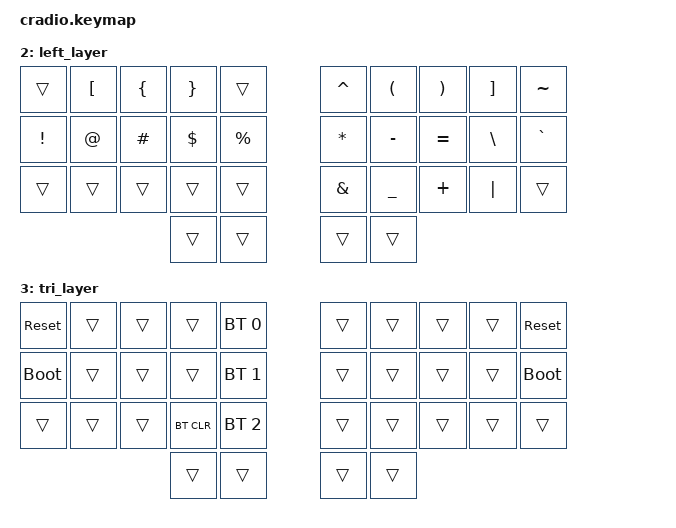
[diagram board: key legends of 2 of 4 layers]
// Copyright (c) 2022 The ZMK Contributors
// SPDX-License-Identifier: MIT

#include <behaviors.dtsi>
#include <dt-bindings/zmk/keys.h>
#include <dt-bindings/zmk/bt.h>


/ {
    behaviors {
        ht: hold_tap {
            label = "hold_tap";
            compatible = "zmk,behavior-hold-tap";
            #binding-cells = <2>;
            flavor = "tap-preferred";
            tapping-term-ms = <220>;
            quick-tap-ms = <150>;
            global-quick-tap;
            bindings = <&kp>, <&kp>;
        };
    };

    conditional_layers {
        compatible = "zmk,conditional-layers";
        tri_layer {
            if-layers = <1 2>;
            then-layer = <3>;
        };
    };

// Home row mods macro
#define HRML(k1,k2,k3,k4) &ht LSHFT k1  &ht LALT k2  &ht LCTRL k3  &ht LGUI k4
#define HRMR(k1,k2,k3,k4) &ht RGUI k1  &ht RCTRL k2  &ht RALT k3  &ht RSHFT k4
    keymap {
        compatible = "zmk,keymap";
        default_layer {
            bindings = <
        //╭──────────┬──────────┬──────────┬──────────┬──────────╮   ╭──────────┬──────────┬──────────┬──────────┬──────────╮
        //│  Q       │  W       │  F       │  P       │  G       │   │  J       │  L       │  U       │  Y       │  ; :     │
            &kp Q       &kp W      &kp E      &kp R      &kp T          &kp Y      &kp U      &kp I      &kp O      &kp P
        //├──────────┼──────────┼──────────┼──────────┼──────────┤   ├──────────┼──────────┼──────────┼──────────┼──────────┤
        //│  A       │  R       │  S       │  T       │  D       │   │  H       │  N       │  E       │  I       │  O       │
            HRML(A,        S,         D,         F)     &kp G          &kp H      HRMR(J,    K,         L,         SEMI)
        //├──────────┼──────────┼──────────┼──────────┼──────────┤   ├──────────┼──────────┼──────────┼──────────┼──────────┤
        //│  / ?     │  Z       │  X       │  C       │  V       │   │  B       │  K       │  M       │ , <      │ . >      │
            &kp FSLH &kp Z   &kp X      &kp C      &kp V             &kp B      &kp N      &kp M      &kp COMMA  &kp DOT
        //╰──────────┴──────────┴──────────┼──────────┼──────────┤   ├──────────┼──────────┼──────────┴──────────┴──────────╯
                                            &lt 2 TAB   &kp ENTER     &kp SPACE  &lt 1 BSPC
        //                                 ╰──────────┴──────────╯   ╰──────────┴──────────╯
            >;
        };

        // Numbers on the left, other symbols on the right
        right_layer {
            bindings = <
        //╭──────────┬──────────┬──────────┬──────────┬──────────╮   ╭──────────┬──────────┬──────────┬──────────┬──────────╮
        //│  Q       │  W       │  F       │  P       │  G       │   │  J       │  L       │  U       │  Y       │  ; :     │
            &kp GRAVE  &kp N4     &kp N5     &kp N6     &kp MINUS      &trans     &trans     &trans     &trans     &kp DEL
        //├──────────┼──────────┼──────────┼──────────┼──────────┤   ├──────────┼──────────┼──────────┼──────────┼──────────┤
        //│  A       │  R       │  S       │  T       │  D       │   │  H       │  N       │  E       │  I       │  O       │
            HRML(N0,      N1,      N2,          N3)     &kp ESC        &trans     HRMR(SQT,  LBKT,      RBKT,      BSLH)
        //├──────────┼──────────┼──────────┼──────────┼──────────┤   ├──────────┼──────────┼──────────┼──────────┼──────────┤
        //│  / ?     │  Z       │  X       │  C       │  V       │   │  B       │  K       │  M       │ , <      │ . >      │
           &caps_word  &kp N7     &kp N8     &kp N9     &kp EQUAL      &trans     &trans     &trans     &trans     &trans
        //╰──────────┴──────────┴──────────┼──────────┼──────────┤   ├──────────┼──────────┼──────────┴──────────┴──────────╯
                                             &trans     &kp ESC        &trans     &trans
        //                                 ╰──────────┴──────────╯   ╰──────────┴──────────╯
            >;
        };

        // idgaf abt this yet
        left_layer {
            bindings = <
        //╭──────────┬──────────┬──────────┬──────────┬──────────╮   ╭──────────┬──────────┬──────────┬──────────┬──────────╮
        //│  Q       │  W       │  F       │  P       │  G       │   │  J       │  L       │  U       │  Y       │  ; :     │
            &trans     &kp LBKT   &kp LBRC   &kp RBRC   &trans         &kp CARET  &kp LPAR   &kp RPAR   &kp RBKT   &kp TILDE
        //├──────────┼──────────┼──────────┼──────────┼──────────┤   ├──────────┼──────────┼──────────┼──────────┼──────────┤
        //│  A       │  R       │  S       │  T       │  D       │   │  H       │  N       │  E       │  I       │  O       │
            &kp EXCL   &kp AT     &kp HASH   &kp DLLR   &kp PRCNT      &kp ASTRK  &kp MINUS  &kp EQUAL  &kp BSLH   &kp GRAVE
        //├──────────┼──────────┼──────────┼──────────┼──────────┤   ├──────────┼──────────┼──────────┼──────────┼──────────┤
        //│  / ?     │  Z       │  X       │  C       │  V       │   │  B       │  K       │  M       │ , <      │ . >      │
            &trans     &trans     &trans     &trans     &trans         &kp AMPS   &kp UNDER  &kp PLUS   &kp PIPE   &trans
        //╰──────────┴──────────┴──────────┼──────────┼──────────┤   ├──────────┼──────────┼──────────┴──────────┴──────────╯
                                             &trans     &trans         &trans     &trans
        //                                 ╰──────────┴──────────╯   ╰──────────┴──────────╯
            >;
        };

        tri_layer {
            bindings = <
        //╭──────────┬──────────┬──────────┬──────────┬──────────╮   ╭──────────┬──────────┬──────────┬──────────┬──────────╮
        //│ RESET    │          │          │          │PROFILE 0 │   │          │          │          │          │  RESET   │
           &sys_reset  &trans     &trans     &trans    &bt BT_SEL 0    &trans     &trans     &trans     &trans    &sys_reset
        //├──────────┼──────────┼──────────┼──────────┼──────────┤   ├──────────┼──────────┼──────────┼──────────┼──────────┤
        //│BOOTLOADER│          │          │          │PROFILE 1 │   │          │          │          │          │BOOTLOADER│
          &bootloader  &trans     &trans     &trans    &bt BT_SEL 1    &trans     &trans     &trans     &trans    &bootloader
        //├──────────┼──────────┼──────────┼──────────┼──────────┤   ├──────────┼──────────┼──────────┼──────────┼──────────┤
        //│          │          │          │ CLEAR BT │PROFILE 2 │   │          │          │          │          │          │
            &trans     &trans     &trans    &bt BT_CLR &bt BT_SEL 2    &trans     &trans     &trans     &trans     &trans
        //╰──────────┴──────────┴──────────┼──────────┼──────────┤   ├──────────┼──────────┼──────────┴──────────┴──────────╯
                                             &trans     &trans         &trans     &trans
        //                                 ╰──────────┴──────────╯   ╰──────────┴──────────╯
            >;
        };
    };
};
